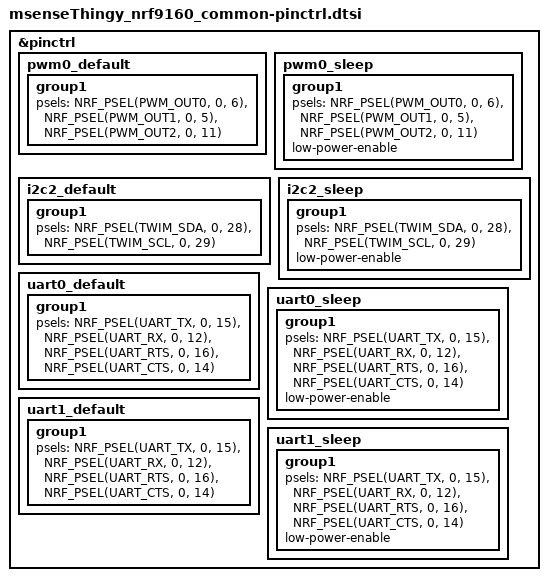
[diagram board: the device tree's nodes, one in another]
&pinctrl {
	pwm0_default: pwm0_default {
		group1 {
			psels = <NRF_PSEL(PWM_OUT0, 0, 6)>,
				<NRF_PSEL(PWM_OUT1, 0, 5)>,
				<NRF_PSEL(PWM_OUT2, 0, 11)>;
		};
	};

	pwm0_sleep: pwm0_sleep {
		group1 {
			psels = <NRF_PSEL(PWM_OUT0, 0, 6)>,
				<NRF_PSEL(PWM_OUT1, 0, 5)>,
				<NRF_PSEL(PWM_OUT2, 0, 11)>;
			low-power-enable;
		};
	};

	i2c2_default: i2c2_default {
		group1 {
			psels = <NRF_PSEL(TWIM_SDA, 0, 28)>,
				<NRF_PSEL(TWIM_SCL, 0, 29)>;
		};
	};

	i2c2_sleep: i2c2_sleep {
		group1 {
			psels = <NRF_PSEL(TWIM_SDA, 0, 28)>,
				<NRF_PSEL(TWIM_SCL, 0, 29)>;
			low-power-enable;
		};
	};

	uart0_default: uart0_default {
		group1 {
			psels = <NRF_PSEL(UART_TX, 0, 15)>,
				<NRF_PSEL(UART_RX, 0, 12)>,
				<NRF_PSEL(UART_RTS, 0, 16)>,
				<NRF_PSEL(UART_CTS, 0, 14)>;
		};
	};

	uart0_sleep: uart0_sleep {
		group1 {
			psels = <NRF_PSEL(UART_TX, 0, 15)>,
				<NRF_PSEL(UART_RX, 0, 12)>,
				<NRF_PSEL(UART_RTS, 0, 16)>,
				<NRF_PSEL(UART_CTS, 0, 14)>;
			low-power-enable;
		};
	};

	uart1_default: uart1_default {
		group1 {
			psels = <NRF_PSEL(UART_TX, 0, 15)>,
				<NRF_PSEL(UART_RX, 0, 12)>,
				<NRF_PSEL(UART_RTS, 0, 16)>,
				<NRF_PSEL(UART_CTS, 0, 14)>;
		};
	};

	uart1_sleep: uart1_sleep {
		group1 {
			psels = <NRF_PSEL(UART_TX, 0, 15)>,
				<NRF_PSEL(UART_RX, 0, 12)>,
				<NRF_PSEL(UART_RTS, 0, 16)>,
				<NRF_PSEL(UART_CTS, 0, 14)>;
			low-power-enable;
		};
	};

};
